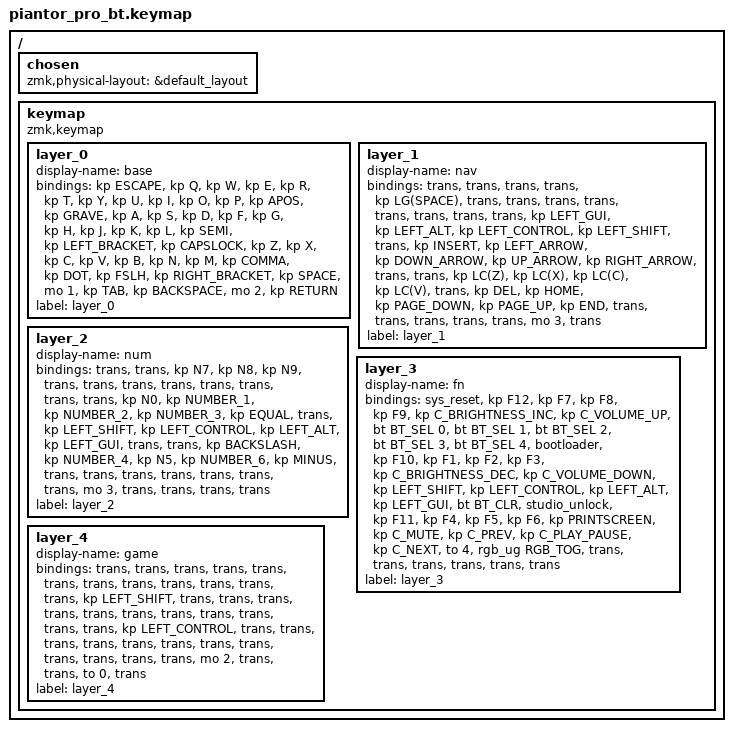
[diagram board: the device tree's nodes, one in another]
/*
 * Copyright (c) 2020 The ZMK Contributors
 *
 * SPDX-License-Identifier: MIT
 */

#include <behaviors.dtsi>
#include <dt-bindings/zmk/bt.h>
#include <dt-bindings/zmk/keys.h>
#include <dt-bindings/zmk/rgb.h>

/ {
    chosen { zmk,physical-layout = &default_layout; };
};

/ {
    keymap {
        compatible = "zmk,keymap";

        layer_0 {
            display-name = "base";

            // --------------------------------------------------------------------------------
            // | ESC |  Q  |  W  |  E  |  R  |  T  |  Y  |  U  |  I  |  O  |  P  |  '   |
            // |  `  |  A  |  S  |  D  |  F  |  G  |  H  |  J  |  K  |  L  |  ;  |  [   |
            // |CAPS |  Z  |  X  |  C  |  V  |  B  |  N  |  M  |  ,  |  .  |  /  |  ]   |
            //                   | SPC | NAV | TAB | BSPC| NUM | RET |

            bindings = <
&kp ESCAPE  &kp Q  &kp W  &kp E  &kp R  &kp T  &kp Y  &kp U  &kp I  &kp O  &kp P  &kp APOS  &kp GRAVE  &kp A  &kp S  &kp D  &kp F  &kp G  &kp H  &kp J  &kp K  &kp L  &kp SEMI  &kp LEFT_BRACKET  &kp CAPSLOCK  &kp Z  &kp X  &kp C  &kp V  &kp B  &kp N  &kp M  &kp COMMA  &kp DOT  &kp FSLH  &kp RIGHT_BRACKET  &kp SPACE  &mo 1  &kp TAB  &kp BACKSPACE  &mo 2  &kp RETURN
            >;

            label = "layer_0";
        };

        layer_1 {
            display-name = "nav";

            // --------------------------------------------------------------------------------
            // |     |     |     |     | GSPC|     |     |     |     |     |     |     |
            // |     | GUI | ALT | CTRL| SHFT|     | INS |  ←  |  ↓  |  ↑  |  →  |     |
            // |     | C-Z | C-X | C-C | C-V |     | DEL | HOME|PGDN |PGUP | END |     |
            //                   |     |     |     |     | FN  |     |

            bindings = <
&trans  &trans  &trans  &trans  &kp LG(SPACE)  &trans  &trans  &trans  &trans  &trans  &trans  &trans  &trans  &kp LEFT_GUI  &kp LEFT_ALT  &kp LEFT_CONTROL  &kp LEFT_SHIFT  &trans  &kp INSERT  &kp LEFT_ARROW  &kp DOWN_ARROW  &kp UP_ARROW  &kp RIGHT_ARROW  &trans  &trans  &kp LC(Z)  &kp LC(X)  &kp LC(C)  &kp LC(V)  &trans  &kp DEL  &kp HOME  &kp PAGE_DOWN  &kp PAGE_UP  &kp END  &trans  &trans  &trans  &trans  &trans  &mo 3  &trans
            >;

            label = "layer_1";
        };

        layer_2 {
            display-name = "num";

            // --------------------------------------------------------------------------------
            // |     |     |  7  |  8  |  9  |     |     |     |     |     |     |     |
            // |     |  0  |  1  |  2  |  3  |  =  |     | SHFT| CTRL| ALT | GUI |     |
            // |     |  \  |  4  |  5  |  6  |  -  |     |     |     |     |     |     |
            //                   |     | FN  |     |     |     |     |

            bindings = <
&trans  &trans  &kp N7  &kp N8  &kp N9  &trans  &trans  &trans  &trans  &trans  &trans  &trans  &trans  &kp N0  &kp NUMBER_1  &kp NUMBER_2  &kp NUMBER_3  &kp EQUAL  &trans  &kp LEFT_SHIFT  &kp LEFT_CONTROL  &kp LEFT_ALT  &kp LEFT_GUI  &trans  &trans  &kp BACKSLASH  &kp NUMBER_4  &kp N5  &kp NUMBER_6  &kp MINUS  &trans  &trans  &trans  &trans  &trans  &trans  &trans  &mo 3  &trans  &trans  &trans  &trans
            >;

            label = "layer_2";
        };

        layer_3 {
            display-name = "fn";

            // --------------------------------------------------------------------------------
            // | RST | F12 | F7  | F8  | F9  | B+  | V+  | BT0 | BT1 | BT2 | BT3 | BT4 |
            // |BOOT | F10 | F1  | F2  | F3  | B-  | V-  | SHFT| CTRL| ALT | GUI | BTCL|
            // |UNLK | F11 | F4  | F5  | F6  | PRSC| MUTE| PREV| PLAY| NEXT| L4  | RGB |
            //                   |     |     |     |     |     |     |

            bindings = <
&sys_reset  &kp F12  &kp F7  &kp F8  &kp F9  &kp C_BRIGHTNESS_INC  &kp C_VOLUME_UP  &bt BT_SEL 0  &bt BT_SEL 1  &bt BT_SEL 2  &bt BT_SEL 3  &bt BT_SEL 4  &bootloader  &kp F10  &kp F1  &kp F2  &kp F3  &kp C_BRIGHTNESS_DEC  &kp C_VOLUME_DOWN  &kp LEFT_SHIFT  &kp LEFT_CONTROL  &kp LEFT_ALT  &kp LEFT_GUI  &bt BT_CLR  &studio_unlock  &kp F11  &kp F4  &kp F5  &kp F6  &kp PRINTSCREEN  &kp C_MUTE  &kp C_PREV  &kp C_PLAY_PAUSE  &kp C_NEXT  &to 4  &rgb_ug RGB_TOG  &trans  &trans  &trans  &trans  &trans  &trans
            >;

            label = "layer_3";
        };

        layer_4 {
            display-name = "game";
            bindings = <
&trans  &trans  &trans  &trans  &trans  &trans  &trans  &trans  &trans  &trans  &trans  &trans  &kp LEFT_SHIFT  &trans  &trans  &trans  &trans  &trans  &trans  &trans  &trans  &trans  &trans  &trans  &kp LEFT_CONTROL  &trans  &trans  &trans  &trans  &trans  &trans  &trans  &trans  &trans  &trans  &trans  &trans  &mo 2  &trans  &trans  &to 0  &trans
            >;

            label = "layer_4";
        };
    };
};
